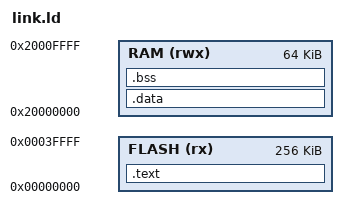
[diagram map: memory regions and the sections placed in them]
/* lm3s6965evb: flash at 0x00000000, RAM at 0x20000000. */
MEMORY {
  FLASH (rx)  : ORIGIN = 0x00000000, LENGTH = 256K
  RAM   (rwx) : ORIGIN = 0x20000000, LENGTH = 64K
}
ENTRY(reset)
SECTIONS {
  .text : { KEEP(*(.vectors)) *(.text*) *(.rodata*) *(.ARM.exidx*) . = ALIGN(4); _etext = .; } > FLASH
  .data : AT(_etext) { _sdata = .; *(.data*) . = ALIGN(4); _edata = .; } > RAM
  .bss  : { _sbss = .; *(.bss*) *(COMMON) . = ALIGN(4); _ebss = .; } > RAM
  _estack = ORIGIN(RAM) + LENGTH(RAM);
}
